# Minimal register map
File version: duplicate
Minimal valid test device
Registers are 32-bit, read-write, no defined reset value unless marked. A register's access mark holds for its fields unless they carry their own. Offsets are from the block's base; lines under a group give offsets from that group; [hi:lo] are bit positions; {n}, {i} and the like mark numbered series; 'fields as' and 'values as' point back to an identical list; <NAME> marks a mode.

## Memory map
0x40000000 TIMER0 size 0x100 — General purpose timer

## TIMER0 — General purpose timer
Base 0x40000000
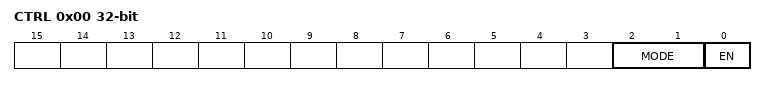
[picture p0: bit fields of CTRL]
0x00 CTRL — Control register
  [2:1] MODE — Timer mode
    0=One-shot mode; 1=Continuous mode
  [0] EN — Timer enable
